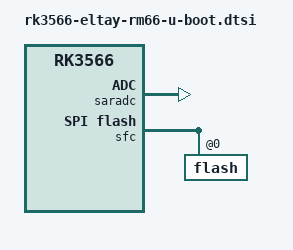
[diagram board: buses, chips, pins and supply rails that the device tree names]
// SPDX-License-Identifier: (GPL-2.0+ OR MIT)

#include "rk356x-u-boot.dtsi"

/ {
	chosen {
		u-boot,spl-boot-order = "same-as-spl", &sdmmc0, &sdhci;
	};

	config {
		u-boot,rockchip-download-key-adc-channel = <0>;
	};
};

&saradc {
	vdd-microvolts = <1800000>;
	status = "okay";
};

&sfc {
	u-boot,spl-sfc-no-dma;

	flash@0 {
		bootph-pre-ram;
		bootph-some-ram;
	};
};
